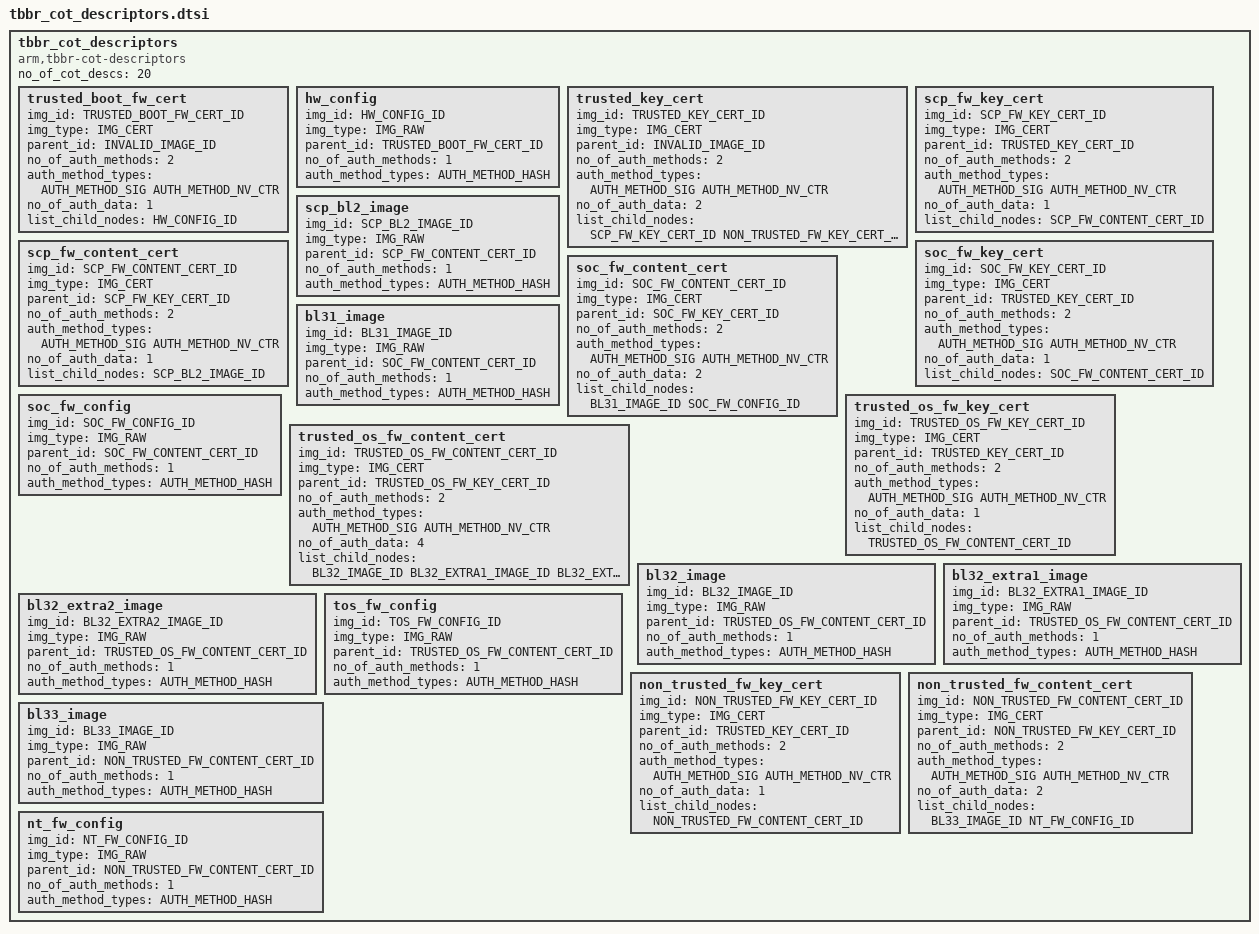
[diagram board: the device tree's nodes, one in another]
/*
 * Copyright (c) 2020, ARM Limited and Contributors. All rights reserved.
 *
 * SPDX-License-Identifier: BSD-3-Clause
 */

#include <dt-bindings/tbbr/tbbr-auth-defs.h>
/*
cot-description {
	compatible = "arm,tbbr-cot-descriptors";

	no_of_cot_descs = <no of cot descriptors>;

	image {
		img_id = <img_id>;
		img_type = <img_type>;
		parent_id = <parent node of this descriptor>;
		no_of_auth_methods = <no of authentication method support>;
		auth_method_types = <list methods of authentication>;
		< Below field are applicable only for IMG_CERT type >
		no_of_auth_data = <no of authentication data>;
		list_child_nodes = <Distinct list of child nodes that uses
				this certificate image for authentication>;
	}
e.g:
	trusted_boot_fw_cert {
		img_id = <TRUSTED_BOOT_FW_CERT_ID>;
		img_type = <IMG_CERT>;
		parent_id = <INVALID_IMAGE_ID>;
		no_of_auth_methods = <2>;
		auth_method_types = <AUTH_METHOD_SIG AUTH_METHOD_NV_CTR>;
		no_of_auth_data = <2>;
		list_child_nodes = <BL2_IMAGE_ID TB_FW_CONFIG_ID HW_CONFIG_ID>;
	};
};
*/

tbbr_cot_descriptors {
	compatible = "arm,tbbr-cot-descriptors";

	no_of_cot_descs = <20>;

	trusted_boot_fw_cert {
		img_id = <TRUSTED_BOOT_FW_CERT_ID>;
		img_type = <IMG_CERT>;
		parent_id = <INVALID_IMAGE_ID>;
		no_of_auth_methods = <2>;
		auth_method_types = <AUTH_METHOD_SIG AUTH_METHOD_NV_CTR>;
		no_of_auth_data = <1>;
		list_child_nodes = <HW_CONFIG_ID>;
	};

	hw_config {
		img_id = <HW_CONFIG_ID>;
		img_type = <IMG_RAW>;
		parent_id = <TRUSTED_BOOT_FW_CERT_ID>;
		no_of_auth_methods = <1>;
		auth_method_types = <AUTH_METHOD_HASH>;
	};

	trusted_key_cert {
		img_id = <TRUSTED_KEY_CERT_ID>;
		img_type = <IMG_CERT>;
		parent_id = <INVALID_IMAGE_ID>;
		no_of_auth_methods = <2>;
		auth_method_types = <AUTH_METHOD_SIG AUTH_METHOD_NV_CTR>;
		no_of_auth_data = <2>;
		list_child_nodes = <SCP_FW_KEY_CERT_ID
				NON_TRUSTED_FW_KEY_CERT_ID>;
	};

	scp_fw_key_cert {
		img_id = <SCP_FW_KEY_CERT_ID>;
		img_type = <IMG_CERT>;
		parent_id = <TRUSTED_KEY_CERT_ID>;
		no_of_auth_methods = <2>;
		auth_method_types = <AUTH_METHOD_SIG AUTH_METHOD_NV_CTR>;
		no_of_auth_data = <1>;
		list_child_nodes = <SCP_FW_CONTENT_CERT_ID>;
	};

	scp_fw_content_cert {
		img_id = <SCP_FW_CONTENT_CERT_ID>;
		img_type = <IMG_CERT>;
		parent_id = <SCP_FW_KEY_CERT_ID>;
		no_of_auth_methods = <2>;
		auth_method_types = <AUTH_METHOD_SIG AUTH_METHOD_NV_CTR>;
		no_of_auth_data = <1>;
		list_child_nodes = <SCP_BL2_IMAGE_ID>;
	};

	scp_bl2_image {
		img_id = <SCP_BL2_IMAGE_ID>;
		img_type = <IMG_RAW>;
		parent_id = <SCP_FW_CONTENT_CERT_ID>;
		no_of_auth_methods = <1>;
		auth_method_types = <AUTH_METHOD_HASH>;
	};

	soc_fw_key_cert {
		img_id = <SOC_FW_KEY_CERT_ID>;
		img_type = <IMG_CERT>;
		parent_id = <TRUSTED_KEY_CERT_ID>;
		no_of_auth_methods = <2>;
		auth_method_types = <AUTH_METHOD_SIG AUTH_METHOD_NV_CTR>;
		no_of_auth_data = <1>;
		list_child_nodes = <SOC_FW_CONTENT_CERT_ID>;
	};

	soc_fw_content_cert {
		img_id = <SOC_FW_CONTENT_CERT_ID>;
		img_type = <IMG_CERT>;
		parent_id = <SOC_FW_KEY_CERT_ID>;
		no_of_auth_methods = <2>;
		auth_method_types = <AUTH_METHOD_SIG AUTH_METHOD_NV_CTR>;
		no_of_auth_data = <2>;
		list_child_nodes = <BL31_IMAGE_ID SOC_FW_CONFIG_ID>;
	};

	bl31_image {
		img_id = <BL31_IMAGE_ID>;
		img_type = <IMG_RAW>;
		parent_id = <SOC_FW_CONTENT_CERT_ID>;
		no_of_auth_methods = <1>;
		auth_method_types = <AUTH_METHOD_HASH>;
	};

	soc_fw_config {
		img_id = <SOC_FW_CONFIG_ID>;
		img_type = <IMG_RAW>;
		parent_id = <SOC_FW_CONTENT_CERT_ID>;
		no_of_auth_methods = <1>;
		auth_method_types = <AUTH_METHOD_HASH>;
	};

	trusted_os_fw_key_cert {
		img_id = <TRUSTED_OS_FW_KEY_CERT_ID>;
		img_type = <IMG_CERT>;
		parent_id = <TRUSTED_KEY_CERT_ID>;
		no_of_auth_methods = <2>;
		auth_method_types = <AUTH_METHOD_SIG AUTH_METHOD_NV_CTR>;
		no_of_auth_data = <1>;
		list_child_nodes = <TRUSTED_OS_FW_CONTENT_CERT_ID>;
	};

	trusted_os_fw_content_cert {
		img_id = <TRUSTED_OS_FW_CONTENT_CERT_ID>;
		img_type = <IMG_CERT>;
		parent_id = <TRUSTED_OS_FW_KEY_CERT_ID>;
		no_of_auth_methods = <2>;
		auth_method_types = <AUTH_METHOD_SIG AUTH_METHOD_NV_CTR>;
		no_of_auth_data = <4>;
		list_child_nodes = <BL32_IMAGE_ID
				BL32_EXTRA1_IMAGE_ID
				BL32_EXTRA2_IMAGE_ID
				TOS_FW_CONFIG_ID>;
	};

	bl32_image {
		img_id = <BL32_IMAGE_ID>;
		img_type = <IMG_RAW>;
		parent_id = <TRUSTED_OS_FW_CONTENT_CERT_ID>;
		no_of_auth_methods = <1>;
		auth_method_types = <AUTH_METHOD_HASH>;
	};

	bl32_extra1_image {
		img_id = <BL32_EXTRA1_IMAGE_ID>;
		img_type = <IMG_RAW>;
		parent_id = <TRUSTED_OS_FW_CONTENT_CERT_ID>;
		no_of_auth_methods = <1>;
		auth_method_types = <AUTH_METHOD_HASH>;
	};

	bl32_extra2_image {
		img_id = <BL32_EXTRA2_IMAGE_ID>;
		img_type = <IMG_RAW>;
		parent_id = <TRUSTED_OS_FW_CONTENT_CERT_ID>;
		no_of_auth_methods = <1>;
		auth_method_types = <AUTH_METHOD_HASH>;
	};

	tos_fw_config {
		img_id = <TOS_FW_CONFIG_ID>;
		img_type = <IMG_RAW>;
		parent_id = <TRUSTED_OS_FW_CONTENT_CERT_ID>;
		no_of_auth_methods = <1>;
		auth_method_types = <AUTH_METHOD_HASH>;
	};

	non_trusted_fw_key_cert {
		img_id = <NON_TRUSTED_FW_KEY_CERT_ID>;
		img_type = <IMG_CERT>;
		parent_id = <TRUSTED_KEY_CERT_ID>;
		no_of_auth_methods = <2>;
		auth_method_types = <AUTH_METHOD_SIG AUTH_METHOD_NV_CTR>;
		no_of_auth_data = <1>;
		list_child_nodes = <NON_TRUSTED_FW_CONTENT_CERT_ID>;
	};

	non_trusted_fw_content_cert {
		img_id = <NON_TRUSTED_FW_CONTENT_CERT_ID>;
		img_type = <IMG_CERT>;
		parent_id = <NON_TRUSTED_FW_KEY_CERT_ID>;
		no_of_auth_methods = <2>;
		auth_method_types = <AUTH_METHOD_SIG AUTH_METHOD_NV_CTR>;
		no_of_auth_data = <2>;
		list_child_nodes = <BL33_IMAGE_ID NT_FW_CONFIG_ID>;
	};

	bl33_image {
		img_id = <BL33_IMAGE_ID>;
		img_type = <IMG_RAW>;
		parent_id = <NON_TRUSTED_FW_CONTENT_CERT_ID>;
		no_of_auth_methods = <1>;
		auth_method_types = <AUTH_METHOD_HASH>;
	};

	nt_fw_config {
		img_id = <NT_FW_CONFIG_ID>;
		img_type = <IMG_RAW>;
		parent_id = <NON_TRUSTED_FW_CONTENT_CERT_ID>;
		no_of_auth_methods = <1>;
		auth_method_types = <AUTH_METHOD_HASH>;
	};
};
